# BAT32A239 register map
Vendor: CMS; Series: BAT32A239; File version: 1.0
CPU: CM0+ r0p1, little endian, MPU, no FPU, VTOR, 2 interrupt priority bits
Registers are 8-bit, read-write, reset 0x0 unless marked. A register's access mark holds for its fields unless they carry their own. Offsets are from the block's base; [hi:lo] are bit positions; {n}, {i} and the like mark numbered series; 'fields as' and 'values as' point back to an identical list.

## CGC — Clock Generate Control
Base 0x40020400
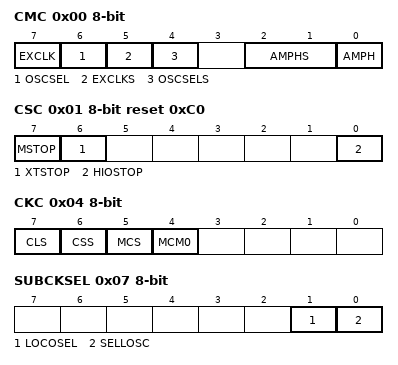
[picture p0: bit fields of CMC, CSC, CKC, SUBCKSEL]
0x00 CMC — Clock operaton Mode Control Register
  [7] EXCLK — External Clock input mode
  [6] OSCSEL — Main OSC Select
  [5] EXCLKS — External Clock input mode
  [4] OSCSELS — Sub OSC Select
  [2:1] AMPHS — Control of XT1 clock oscillation frequency
  [0] AMPH — Control of X1 clock oscillation frequency
0x01 CSC reset 0xC0 — Clock operation Status Register
  [7] MSTOP — High-speed system clock operation control
    0=START (X1 oscillator operating or External clock from EXCLK pin is valid); 1=STOP (X1 oscillator stop or External clock from EXCLK pin is invalid)
  [6] XTSTOP — Subsystem clock operation control
    0=START (XT1 oscillator operating or External clock from EXCLKS pin is valid); 1=STOP (XT1 oscillator stop or External clock from EXCLKS pin is invalid)
  [0] HIOSTOP — High-speed on-chip oscillator clock operation control
    0=START (High-speed on-chip oscillator operating); 1=STOP (High-speed on-chip oscillator stopped)
0x02 OSTC ro — Oscillation stabilization time counter status
0x03 OSTS reset 0x7 (reset mask 0x7) — Oscillation stabilization time select register
0x04 CKC — System clock control register
  [7] CLS ro — Status of CPU/peripheral hardware clock (fCLK)
    0=fMAIN (Main system clock (fMAIN)); 1=fSUB (Subsystem clock (fSUB))
  [6] CSS — Selection of CPU/peripheral hardware clock (fCLK)
    values as CLS
  [5] MCS ro — Status of Main system clock (fMAIN)
    0=fIH (High-speed on-chip oscillator clock (fIH)); 1=fMX (High-speed system clock (fMX))
  [4] MCM0 — Main system clock (fMAIN) operation control
    0=fIH (Select the high-speed on-chip oscillator clock (fIH) as the main system clock (fMAIN)); 1=fMX (Select the high-speed system clock (fMX) as the main system clock (fMAIN))
0x05 LOCKCTL (reset mask 0x1) — Lockup Watchdog timer enable register
0x06 PRCR — Lockup Watchdog timer enable protect register
0x07 SUBCKSEL — Subsystem Clock select register
  [1] LOCOSEL — SUBOSC speed select
    0=SUB_15K (Select 15k for SUBOSC clock); 1=SUB_30K (Select 30k for SUBOSC clock)
  [0] SELLOSC — Select LOSC or SUBOSC
    0=SUBOSC (Select SUBOSC as the SubSystem clock); 1=LOSC (Select LOSC as the SubSystem clock)
{0x8+i} WDTCFG{i} (i=0..3) — WDT Configeration {i} register
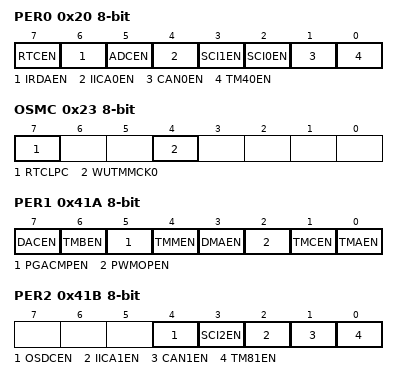
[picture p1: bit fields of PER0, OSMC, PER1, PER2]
0x20 PER0 — Peripheral enable register 0
  [all] fields
    0=Disabled (Disables input clock supply); 1=Enables input clock supply
  [7] RTCEN — Control of the RTC input clock
  [6] IRDAEN — Control of the IRDA input clock
  [5] ADCEN — Control of the ADC input clock
  [4] IICA0EN — Control of the IICA0 input clock
  [3] SCI1EN — Control of the SCI1 input clock
  [2] SCI0EN — Control of the SCI0 input clock
  [1] CAN0EN — Control of the CAN0 input clock
  [0] TM40EN — Control of the TM4 input clock
0x23 OSMC (reset mask 0x88) — Subsystem clock supply mode control register
  [7] RTCLPC — Setting in DEEPSLEEP mode or SLEEP mode while subsystem clock is selected as CPU clock
    0=Enables supply of subsystem clock to peripheral function; 1=Disable (Stops supply of subsystem clock to peripheral functions other than real-time clock and 15-bit interval timer.)
  [4] WUTMMCK0 — Selection of operation clock for real-time clock, 15-bit interval timer, and timer A
    0=fSUB (The subsystem clock is selected as the operation clock for the real-time clock and the 15-bit interval timer. The low-speed on-chip oscillator cannot be selected as the count source for timer A.); 1=fIL (The low-speed on-chip oscillator clock is selected as the operation clock for the real-time clock and the 15-bit interval timer. Either the low-speed on-chip oscillator or the subsystem clock can be selected as the count source for timer A.)
0x41A PER1 — Peripheral enable register 1
  [all] fields
    values as the fields of PER0
  [7] DACEN — Control of the DAC input clock
  [6] TMBEN — Control of the TMB input clock
  [5] PGACMPEN — Control of the PGACMP input clock
  [4] TMMEN — Control of the TMM input clock
  [3] DMAEN — Control of the DMA input clock
  [2] PWMOPEN — Control of the PWMOP input clock
  [1] TMCEN — Control of the TMC input clock
  [0] TMAEN — Control of the TMA input clock
0x41B PER2 — Peripheral enable register 2
  [all] fields
    values as the fields of PER0
  [4] OSDCEN — Control of the oscillator stop detection input clock
  [3] SCI2EN — Control of the SCI2 input clock
  [2] IICA1EN — Control of the IICA1 input clock
  [1] CAN1EN — Control of the CAN1 input clock
  [0] TM81EN — Control of the TM8 input clock
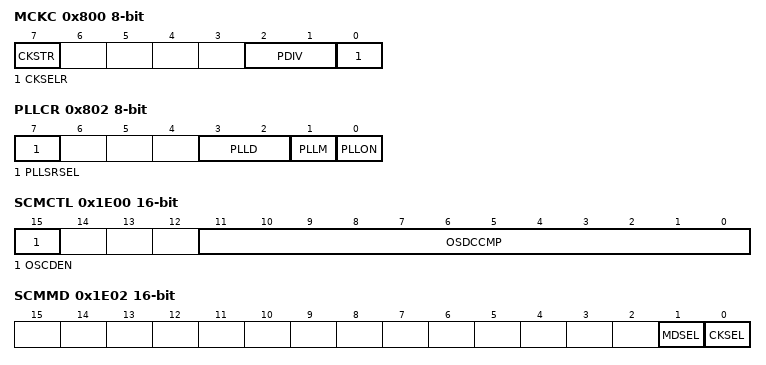
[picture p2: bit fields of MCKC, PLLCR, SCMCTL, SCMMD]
0x800 MCKC (reset mask 0x17) — Main system clock control register
  [7] CKSTR ro — Status of Main system clock (fMAIN)
    0=fIH (High-speed on-chip oscillator clock (fIH)); 1=fPLL (PLL clock (fPLL))
  [2:1] PDIV — PLL frequency select register
  [0] CKSELR — Select f(IH) or f(PLL)
    0=fIH (Select the high-speed on-chip oscillator clock (fIH) as the main system clock (fMAIN)); 1=PLL (Select the PLL clock (fPLL) as the main system clock (fMAIN))
0x802 PLLCR — System PLL clock control register
  [7] PLLSRSEL ro — PLL input clock source select
    0=fIH (Select the high-speed on-chip oscillator clock (fIH) as PLL input source); 1=fMX (Select external main system clock f(MX) as PLL input source)
  [3:2] PLLD — PLL frequency division ratio select
  [1] PLLM — PLL frequency multiplication factor select
    0=X12 (PLL multiplication factor is 12); 1=X16 (PLL multiplication factor is 16)
  [0] PLLON — PLL operation control
    0=PLL STOP (PLL is stopped); 1=PLL ON (PLL is operating)
0x1800 HIOTRM (reset mask 0x3F) — High-speed on-chip oscillator trimming register
0x1820 HOCODIV (reset mask 0x7) — High-speed on-chip oscillator frequency select register
0x1E00 SCMCTL 16-bit — Oscillator stop detection control register
  [15] OSCDEN — Oscillator stop detection control register
    1=START (Oscillator stop detection start); 0=STOP (Oscillator stop detection stop)
  [11:0] OSDCCMP — Oscillator stop detected time register
0x1E02 SCMMD 16-bit — Oscillator stop detection mode register
  [1] MDSEL — Oscillator stop detected operation selection register
    0=INT (Interrupt when oscillator stop detection); 1=RESET (Reset when oscillator stop detection)
  [0] CKSEL — Oscillator stop detected object selection register
    0=fMX (fMX Oscillator stop detection); 1=fSX (fSX Oscillator stop detection)
0x1E04 SCMST — Oscillator stop detected status register
  [0] OSTDF — Oscillator stop detected flag register
    0=NoDetection (Oscillator stop NOT detection); 1=Detection (Oscillator stop detection)
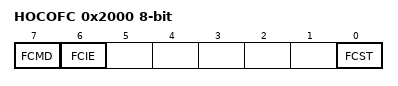
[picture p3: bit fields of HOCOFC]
0x2000 HOCOFC — High-speed on-chip oscillator frequency correction register
  [7] FCMD — High-speed on-chip oscillator frequency correction operation mode register
  [6] FCIE — Oscillator stop detected operation selection register
  [0] FCST — Oscillator stop detected object selection register

## Notices in the file
Copyright (C) 2012-2014 ARM Limited. All rights reserved.
Purpose: System Viewer Description (SVD) Example (Schema Version 1.1)
This is a description of a none-existent and incomplete device
for demonstration purposes only.
Redistribution and use in source and binary forms, with or without
modification, are permitted provided that the following conditions are met:
- Redistributions of source code must retain the above copyright
notice, this list of conditions and the following disclaimer.
- Redistributions in binary form must reproduce the above copyright
notice, this list of conditions and the following disclaimer in the
documentation and/or other materials provided with the distribution.
- Neither the name of ARM nor the names of its contributors may be used
to endorse or promote products derived from this software without
specific prior written permission.
THIS SOFTWARE IS PROVIDED BY THE COPYRIGHT HOLDERS AND CONTRIBUTORS "AS IS"
AND ANY EXPRESS OR IMPLIED WARRANTIES, INCLUDING, BUT NOT LIMITED TO, THE
IMPLIED WARRANTIES OF MERCHANTABILITY AND FITNESS FOR A PARTICULAR PURPOSE
ARE DISCLAIMED. IN NO EVENT SHALL COPYRIGHT HOLDERS AND CONTRIBUTORS BE
LIABLE FOR ANY DIRECT, INDIRECT, INCIDENTAL, SPECIAL, EXEMPLARY, OR
CONSEQUENTIAL DAMAGES (INCLUDING, BUT NOT LIMITED TO, PROCUREMENT OF
SUBSTITUTE GOODS OR SERVICES; LOSS OF USE, DATA, OR PROFITS; OR BUSINESS
INTERRUPTION) HOWEVER CAUSED AND ON ANY THEORY OF LIABILITY, WHETHER IN
CONTRACT, STRICT LIABILITY, OR TORT (INCLUDING NEGLIGENCE OR OTHERWISE)
ARISING IN ANY WAY OUT OF THE USE OF THIS SOFTWARE, EVEN IF ADVISED OF THE
POSSIBILITY OF SUCH DAMAGE.
